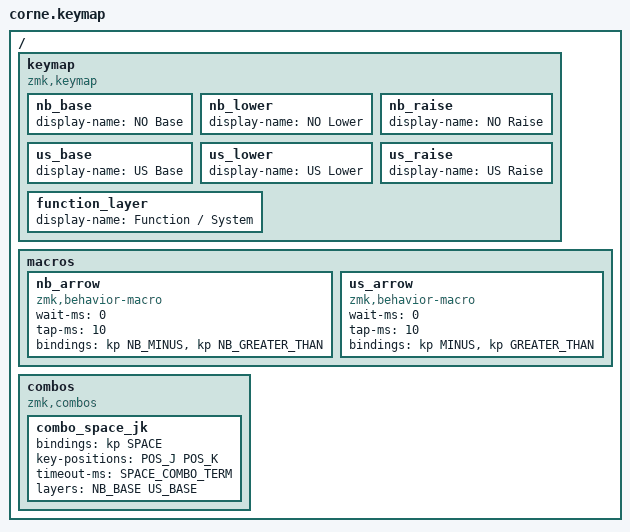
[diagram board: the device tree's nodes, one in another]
/*
 * Copyright (c) 2020 The ZMK Contributors
 *
 * SPDX-License-Identifier: MIT
 *
 * Dual host-locale Corne keymap optimized for Rust/C, Neovim and terminal use.
 *
 * Default mode: Norwegian host layout.
 * Toggle US mode: Lower + physical Z position.
 * Norwegian extras: Lower + M/,/. => æ/ø/å.
 * Base: J+K Space, left thumb Shift, Delete below Backspace.
 * Raise (left layer thumb): full symbol fallback palette + right-side numpad.
 * Lower (right layer thumb): media + Vim H/J/K/L navigation.
 * Function layer: hold both layer thumbs; F1-F12 + guarded BT clear.
 * Programming symbols: high-frequency Base combos; Raise provides direct fallbacks.
 */

#include <behaviors.dtsi>
#include <dt-bindings/zmk/keys.h>
#include <dt-bindings/zmk/bt.h>

#include "key_positions.h"

/* Norwegian is the power-on default. US_BASE is a persistent overlay. */
#define NB_BASE  0
#define NB_LOWER 1
#define NB_RAISE 2
#define US_BASE  3
#define US_LOWER 4
#define US_RAISE 5
#define FUNCTION_LAYER 6

#define PROGRAMMING_COMBO_TERM 40
#define SPACE_COMBO_TERM       50

/* Compile the first group using Norwegian host-layout semantics. */
#define ZMK_KEYMAP_COMPAT_NB
#include "keys_locale_compat.h"
#undef ZMK_KEYMAP_COMPAT_NB

#define LOWER_LAYER NB_LOWER
#define RAISE_LAYER NB_RAISE

/ {
    keymap {
        compatible = "zmk,keymap";

        nb_base {
            display-name = "NO Base";
#include "layers/base.inc"
        };

        nb_lower {
            display-name = "NO Lower";
#include "layers/lower.inc"
        };

        nb_raise {
            display-name = "NO Raise";
#include "layers/raise.inc"
        };

        /* Restore standard ZMK/US semantic names, then instantiate the same
         * shared layer sources for US-host mode.
         */
#undef LOWER_LAYER
#undef RAISE_LAYER
#include "keys_locale_compat.h"
#define LOWER_LAYER US_LOWER
#define RAISE_LAYER US_RAISE

        us_base {
            display-name = "US Base";
#include "layers/base.inc"
        };

        us_lower {
            display-name = "US Lower";
#include "layers/lower.inc"
        };

        us_raise {
            display-name = "US Raise";
#include "layers/raise.inc"
        };

        function_layer {
            display-name = "Function / System";
#include "layers/function.inc"
        };
    };

    /* Locale-specific text macros. Macro definitions appear after the keymap
     * so semantic names are currently restored to US, while NB_* aliases from
     * keys_nb.h remain available for the Norwegian version.
     */
    macros {
        nb_arrow: nb_arrow {
            compatible = "zmk,behavior-macro";
            #binding-cells = <0>;
            wait-ms = <0>;
            tap-ms = <10>;
            bindings = <&kp NB_MINUS &kp NB_GREATER_THAN>;
        };

        us_arrow: us_arrow {
            compatible = "zmk,behavior-macro";
            #binding-cells = <0>;
            wait-ms = <0>;
            tap-ms = <10>;
            bindings = <&kp MINUS &kp GREATER_THAN>;
        };
    };

    combos {
        compatible = "zmk,combos";

        /* Existing J+K Space chord, valid only on either Base mode. */
        combo_space_jk {
            bindings = <&kp SPACE>;
            key-positions = <POS_J POS_K>;
            timeout-ms = <SPACE_COMBO_TERM>;
            layers = <NB_BASE US_BASE>;
        };

        /* Emit the same combo geometry twice. Key combos use localized
         * semantic keycodes; action combos select the locale-specific macro.
         */
#define PROGRAMMING_COMBO(name, semantic_key, pos1, pos2) \
        nb_combo_##name { \
            bindings = <&kp NB_##semantic_key>; \
            key-positions = <pos1 pos2>; \
            timeout-ms = <PROGRAMMING_COMBO_TERM>; \
            layers = <NB_BASE>; \
        };
#define PROGRAMMING_ACTION_COMBO(name, behavior, pos1, pos2) \
        nb_combo_##name { \
            bindings = <&nb_##behavior>; \
            key-positions = <pos1 pos2>; \
            timeout-ms = <PROGRAMMING_COMBO_TERM>; \
            layers = <NB_BASE>; \
        };
#include "combos/programming.inc"
#undef PROGRAMMING_ACTION_COMBO
#undef PROGRAMMING_COMBO

#define PROGRAMMING_COMBO(name, semantic_key, pos1, pos2) \
        us_combo_##name { \
            bindings = <&kp semantic_key>; \
            key-positions = <pos1 pos2>; \
            timeout-ms = <PROGRAMMING_COMBO_TERM>; \
            layers = <US_BASE>; \
        };
#define PROGRAMMING_ACTION_COMBO(name, behavior, pos1, pos2) \
        us_combo_##name { \
            bindings = <&us_##behavior>; \
            key-positions = <pos1 pos2>; \
            timeout-ms = <PROGRAMMING_COMBO_TERM>; \
            layers = <US_BASE>; \
        };
#include "combos/programming.inc"
#undef PROGRAMMING_ACTION_COMBO
#undef PROGRAMMING_COMBO
    };
};
